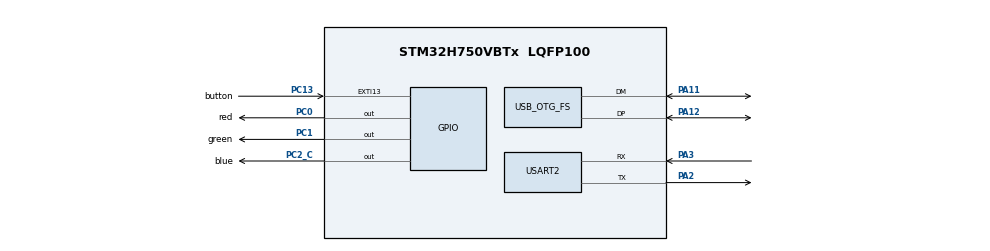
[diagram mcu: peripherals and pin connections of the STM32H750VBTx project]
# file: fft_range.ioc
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Mcu.Family=STM32H7
Mcu.Name=STM32H750VBTx
Mcu.Package=LQFP100
NVIC.EXTI15_10_IRQn=true\:0\:0\:false\:false\:true\:true\:true\:true
NVIC.OTG_FS_IRQn=true\:0\:0\:true\:false\:true\:false\:true\:true
NVIC.PriorityGroup=NVIC_PRIORITYGROUP_4
NVIC.USART2_IRQn=true\:0\:0\:false\:false\:true\:true\:true\:true
PA11.GPIO_Speed=GPIO_SPEED_FREQ_VERY_HIGH
PA11.Mode=Device_Only
PA11.Signal=USB_OTG_FS_DM
PA12.GPIO_Speed=GPIO_SPEED_FREQ_VERY_HIGH
PA12.Mode=Device_Only
PA12.Signal=USB_OTG_FS_DP
PA13\ (JTMS/SWDIO).Mode=Serial_Wire
PA13\ (JTMS/SWDIO).Signal=DEBUG_JTMS-SWDIO
PA14\ (JTCK/SWCLK).Mode=Serial_Wire
PA14\ (JTCK/SWCLK).Signal=DEBUG_JTCK-SWCLK
PA2.Mode=Asynchronous
PA2.Signal=USART2_TX
PA3.Mode=Asynchronous
PA3.Signal=USART2_RX
PC0.GPIO_Label=red
PC0.GPIO_PuPd=GPIO_PULLDOWN
PC0.PinState=GPIO_PIN_SET
PC0.Signal=GPIO_Output
PC1.GPIO_Label=green
PC1.GPIO_PuPd=GPIO_PULLDOWN
PC1.PinState=GPIO_PIN_SET
PC1.Signal=GPIO_Output
PC13.GPIO_Label=button
PC13.GPIO_ModeDefaultEXTI=GPIO_MODE_IT_RISING
PC13.GPIO_PuPd=GPIO_PULLUP
PC13.Signal=GPXTI13
PC14-OSC32_IN\ (OSC32_IN).Mode=LSE-External-Oscillator
PC14-OSC32_IN\ (OSC32_IN).Signal=RCC_OSC32_IN
PC15-OSC32_OUT\ (OSC32_OUT).Mode=LSE-External-Oscillator
PC15-OSC32_OUT\ (OSC32_OUT).Signal=RCC_OSC32_OUT
PC2_C.GPIO_Label=blue
PC2_C.GPIO_PuPd=GPIO_PULLDOWN
PC2_C.PinState=GPIO_PIN_SET
PC2_C.Signal=GPIO_Output
PH0-OSC_IN\ (PH0).Mode=HSE-External-Oscillator
PH0-OSC_IN\ (PH0).Signal=RCC_OSC_IN
PH1-OSC_OUT\ (PH1).Mode=HSE-External-Oscillator
PH1-OSC_OUT\ (PH1).Signal=RCC_OSC_OUT
ProjectManager.HeapSize=0x3000
ProjectManager.StackSize=0x400
ProjectManager.TargetToolchain=STM32CubeIDE
RCC.ADCFreq_Value=24187500
RCC.APB1Freq_Value=120000000
RCC.APB2Freq_Value=120000000
RCC.APB3Freq_Value=120000000
RCC.APB4Freq_Value=120000000
RCC.CortexFreq_Value=480000000
RCC.D1PPRE=RCC_APB3_DIV2
RCC.D2PPRE1=RCC_APB1_DIV2
RCC.D2PPRE2=RCC_APB2_DIV2
RCC.D3PPRE=RCC_APB4_DIV2
RCC.DIVM1=1
RCC.DIVM3=10
RCC.DIVN1=80
RCC.DIVN3=170
RCC.DIVQ3=4
RCC.EnbaleCSS=true
RCC.HCLKFreq_Value=240000000
RCC.HPRE=RCC_HCLK_DIV2
RCC.HSE_VALUE=12000000
RCC.PLLSourceVirtual=RCC_PLLSOURCE_HSE
RCC.SYSCLKFreq_VALUE=480000000
RCC.SYSCLKSource=RCC_SYSCLKSOURCE_PLLCLK
RCC.USBCLockSelection=RCC_USBCLKSOURCE_PLL3
RCC.USBFreq_Value=51000000
STMicroelectronics.X-CUBE-ALGOBUILD.1.3.0.LibraryCcDSPOoLibraryJjDSPOoLibrary=true
USART2.VirtualMode-Asynchronous=VM_ASYNC
USB_DEVICE.APP_RX_DATA_SIZE-CDC_FS=2048
USB_DEVICE.CLASS_NAME_FS=CDC
USB_DEVICE.VirtualMode-CDC_FS=Cdc
USB_DEVICE.VirtualModeFS=Cdc_FS
USB_OTG_FS.VirtualMode=Device_Only
VP_STMicroelectronics.X-CUBE-ALGOBUILD_VS_DSPOoLibraryJjLibrary_1.3.0_1.3.0.Mode=DSPOoLibraryJjLibrary
VP_USB_DEVICE_VS_USB_DEVICE_CDC_FS.Mode=CDC_FS
board=custom

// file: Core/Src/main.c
/* USER CODE BEGIN Header */
/**
  ******************************************************************************
  * @file           : main.c
  * @brief          : Main program body
  ******************************************************************************
  * @attention
  *
  * Copyright (c) 2022 STMicroelectronics.
  * All rights reserved.
  *
  * This software is licensed under terms that can be found in the LICENSE file
  * in the root directory of this software component.
  * If no LICENSE file comes with this software, it is provided AS-IS.
  *
  ******************************************************************************
  */
/* USER CODE END Header */
#include "main.h"
#include "usart.h"
#include "usb_device.h"
#include "gpio.h"

/* USER CODE BEGIN Includes */
#include "usbd_cdc_if.h"
/* USER CODE END Includes */

void SystemClock_Config(void);

int main(void)
{

  /* MCU Configuration--------------------------------------------------------*/

  /* Reset of all peripherals, Initializes the Flash interface and the Systick. */
  HAL_Init();

  /* Configure the system clock */
  SystemClock_Config();

  /* Initialize all configured peripherals */
  MX_GPIO_Init();
  MX_USB_DEVICE_Init();
  MX_USART2_UART_Init();
  /* USER CODE BEGIN 2 */
  HAL_GPIO_WritePin(GPIOC, green_Pin, GPIO_PIN_RESET);
  for(uint32_t num = 0; num < APP_RX_DATA_SIZE; num++)
  {
  	UserRxBufferFS[num] = '-';
  }
  HAL_GPIO_WritePin(GPIOC, green_Pin, GPIO_PIN_SET);
  //HAL_GPIO_WritePin(GPIOC, red_Pin|green_Pin|blue_Pin, GPIO_PIN_RESET);
  /* USER CODE END 2 */

  /* Infinite loop */
  /* USER CODE BEGIN WHILE */
  while (1)
  {
	  HAL_GPIO_WritePin(GPIOC, red_Pin, GPIO_PIN_RESET);
    /* USER CODE END WHILE */

  }
}

void SystemClock_Config(void)
{
  RCC_OscInitTypeDef RCC_OscInitStruct = {0};
  RCC_ClkInitTypeDef RCC_ClkInitStruct = {0};

  /** Supply configuration update enable
  */
  HAL_PWREx_ConfigSupply(PWR_LDO_SUPPLY);

  /** Configure the main internal regulator output voltage
  */
  __HAL_PWR_VOLTAGESCALING_CONFIG(PWR_REGULATOR_VOLTAGE_SCALE0);

  while(!__HAL_PWR_GET_FLAG(PWR_FLAG_VOSRDY)) {}

  /** Macro to configure the PLL clock source
  */
  __HAL_RCC_PLL_PLLSOURCE_CONFIG(RCC_PLLSOURCE_HSE);

  /** Initializes the RCC Oscillators according to the specified parameters
  * in the RCC_OscInitTypeDef structure.
  */
  RCC_OscInitStruct.OscillatorType = RCC_OSCILLATORTYPE_HSE;
  RCC_OscInitStruct.HSEState = RCC_HSE_ON;
  RCC_OscInitStruct.PLL.PLLState = RCC_PLL_ON;
  RCC_OscInitStruct.PLL.PLLSource = RCC_PLLSOURCE_HSE;
  RCC_OscInitStruct.PLL.PLLM = 1;
  RCC_OscInitStruct.PLL.PLLN = 80;
  RCC_OscInitStruct.PLL.PLLP = 2;
  RCC_OscInitStruct.PLL.PLLQ = 2;
  RCC_OscInitStruct.PLL.PLLR = 2;
  RCC_OscInitStruct.PLL.PLLRGE = RCC_PLL1VCIRANGE_3;
  RCC_OscInitStruct.PLL.PLLVCOSEL = RCC_PLL1VCOWIDE;
  RCC_OscInitStruct.PLL.PLLFRACN = 0;
  if (HAL_RCC_OscConfig(&RCC_OscInitStruct) != HAL_OK)
  {
    Error_Handler();
  }

  /** Initializes the CPU, AHB and APB buses clocks
  */
  RCC_ClkInitStruct.ClockType = RCC_CLOCKTYPE_HCLK|RCC_CLOCKTYPE_SYSCLK
                              |RCC_CLOCKTYPE_PCLK1|RCC_CLOCKTYPE_PCLK2
                              |RCC_CLOCKTYPE_D3PCLK1|RCC_CLOCKTYPE_D1PCLK1;
  RCC_ClkInitStruct.SYSCLKSource = RCC_SYSCLKSOURCE_PLLCLK;
  RCC_ClkInitStruct.SYSCLKDivider = RCC_SYSCLK_DIV1;
  RCC_ClkInitStruct.AHBCLKDivider = RCC_HCLK_DIV2;
  RCC_ClkInitStruct.APB3CLKDivider = RCC_APB3_DIV2;
  RCC_ClkInitStruct.APB1CLKDivider = RCC_APB1_DIV2;
  RCC_ClkInitStruct.APB2CLKDivider = RCC_APB2_DIV2;
  RCC_ClkInitStruct.APB4CLKDivider = RCC_APB4_DIV2;

  if (HAL_RCC_ClockConfig(&RCC_ClkInitStruct, FLASH_LATENCY_4) != HAL_OK)
  {
    Error_Handler();
  }

  /** Enables the Clock Security System
  */
  HAL_RCC_EnableCSS();
}

/* USER CODE BEGIN 4 */
void HAL_GPIO_EXTI_Callback(uint16_t GPIO_Pin)
{
	if(GPIO_Pin == button_Pin)
	{
		CDC_Transmit_FS((uint8_t *)UserRxBufferFS, 100);
		usb_debug("\r\n");
	}
}
/* USER CODE END 4 */

void Error_Handler(void)
{
  __disable_irq();
  while (1)
  {
  }
}
